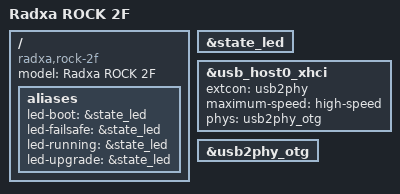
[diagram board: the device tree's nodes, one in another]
// SPDX-License-Identifier: (GPL-2.0+ OR MIT)

/dts-v1/;

#include "rk3528-rock-2.dtsi"

/ {
	model = "Radxa ROCK 2F";
	compatible = "radxa,rock-2f", "rockchip,rk3528";

	aliases {
		led-boot = &state_led;
		led-failsafe = &state_led;
		led-running = &state_led;
		led-upgrade = &state_led;
	};
};

&state_led {
	/delete-property/ default-state;
	/delete-property/ linux,default-trigger;
};

&usb_host0_xhci {
	extcon = <&usb2phy>;
	maximum-speed = "high-speed";
	phys = <&usb2phy_otg>;
	phy-names = "usb2-phy";
	status = "okay";
};

&usb2phy_otg {
	status = "okay";
};
